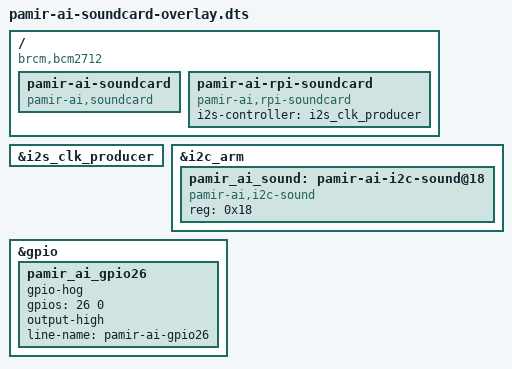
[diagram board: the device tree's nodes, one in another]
// SPDX-License-Identifier: GPL-2.0-only
/*
 * Device Tree overlay for PamirAI soundcard
 */

/dts-v1/;
/plugin/;

/ {
	compatible = "brcm,bcm2712";

	fragment@0 {
		target = <&i2s_clk_producer>;
		__overlay__ {
			status = "okay";
		};
	};

	fragment@1 {
		target-path = "/";
		__overlay__ {
			pamir-ai-soundcard {
				#sound-dai-cells = <0>;
				compatible = "pamir-ai,soundcard";
				status = "okay";
			};

			pamir-ai-rpi-soundcard {
				compatible = "pamir-ai,rpi-soundcard";
				i2s-controller = <&i2s_clk_producer>;
				status = "okay";
			};
		};
	};

	fragment@3 {
		target = <&i2c_arm>;
		__overlay__ {
			#address-cells = <1>;
			#size-cells = <0>;
			status = "okay";

			pamir_ai_sound: pamir-ai-i2c-sound@18 {
				reg = <0x18>;
				compatible = "pamir-ai,i2c-sound";
				status = "okay";
			};
		};
	};

	/* fragment@4: reserve GPIO26 as output-high at boot */
	fragment@4 {
		target = <&gpio>;
		__overlay__ {
			pamir_ai_gpio26 {
				gpio-hog;
				/* GPIO number, active-high */
				gpios = <26 0>;
				output-high;
				line-name = "pamir-ai-gpio26";
			};
		};
	};
};
